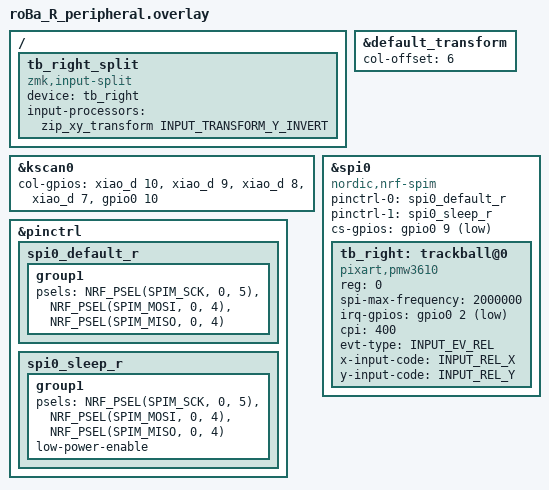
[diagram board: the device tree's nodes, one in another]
#include <zephyr/dt-bindings/pinctrl/nrf-pinctrl.h>
#include "roBa.dtsi"
#include <input/processors.dtsi>

&default_transform {
    col-offset = <6>;
};

&kscan0 {
    col-gpios
        = <&xiao_d 10 GPIO_ACTIVE_HIGH>
        , <&xiao_d 9 GPIO_ACTIVE_HIGH>
        , <&xiao_d 8 GPIO_ACTIVE_HIGH>
        , <&xiao_d 7 GPIO_ACTIVE_HIGH>
        , <&gpio0 10 GPIO_ACTIVE_HIGH>
        ;
};

&pinctrl {
    spi0_default_r: spi0_default_r {
        group1 {
            psels = <NRF_PSEL(SPIM_SCK, 0, 5)>,
                    <NRF_PSEL(SPIM_MOSI, 0, 4)>,
                    <NRF_PSEL(SPIM_MISO, 0, 4)>;
        };
    };

    spi0_sleep_r: spi0_sleep_r {
        group1 {
            psels = <NRF_PSEL(SPIM_SCK, 0, 5)>,
                    <NRF_PSEL(SPIM_MOSI, 0, 4)>,
                    <NRF_PSEL(SPIM_MISO, 0, 4)>;
            low-power-enable;
        };
    };
};

&spi0 {
    status = "okay";
    compatible = "nordic,nrf-spim";
    pinctrl-0 = <&spi0_default_r>;
    pinctrl-1 = <&spi0_sleep_r>;
    pinctrl-names = "default", "sleep";
    cs-gpios = <&gpio0 9 GPIO_ACTIVE_LOW>;

    tb_right: trackball@0 {
        status = "okay";
        compatible = "pixart,pmw3610";
        reg = <0>;
        spi-max-frequency = <2000000>;
        irq-gpios = <&gpio0 2 (GPIO_ACTIVE_LOW | GPIO_PULL_UP)>;

        cpi = <400>;

        evt-type = <INPUT_EV_REL>;
        x-input-code = <INPUT_REL_X>;
        y-input-code = <INPUT_REL_Y>;
    };
};

/ {
    tb_right_split: tb_right_split {
        compatible = "zmk,input-split";
        device = <&tb_right>;
        input-processors = <&zip_xy_transform INPUT_TRANSFORM_Y_INVERT>;
    };
};
